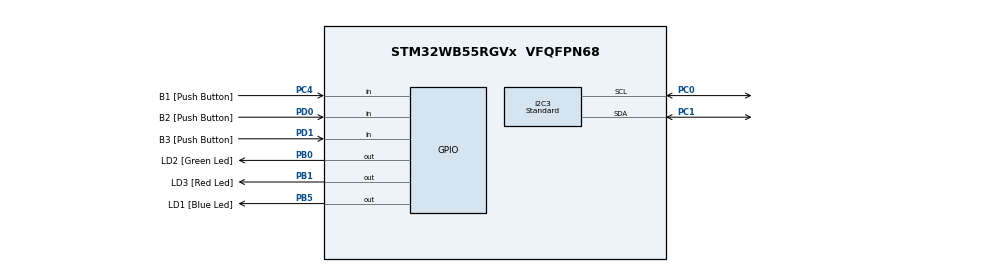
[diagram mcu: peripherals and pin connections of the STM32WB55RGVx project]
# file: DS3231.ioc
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I2C3.I2C_Speed_Mode=I2C_Standard
I2C3.Timing=0x00B07CB4
Mcu.Family=STM32WB
Mcu.Name=STM32WB55RGVx
Mcu.Package=VFQFPN68
NUCLEO-WB55RG.VCP=true
NVIC.PriorityGroup=NVIC_PRIORITYGROUP_4
OSC_IN.GPIO_Label=RCC_OSC_IN
OSC_IN.Signal=RCC_OSC_IN
OSC_OUT.GPIO_Label=RCC_OSC_OUT
OSC_OUT.Signal=RCC_OSC_OUT
PA11.GPIO_Label=USB_DM
PA11.Signal=USB_DM
PA12.GPIO_Label=USB_DP
PA12.Signal=USB_DP
PA13.GPIO_Label=JTMS
PA13.Signal=SYS_JTMS-SWDIO
PA14.GPIO_Label=JTCK
PA14.Signal=SYS_JTCK-SWCLK
PB0.GPIO_Label=LD2 [Green Led]
PB0.Signal=GPIO_Output
PB1.GPIO_Label=LD3 [Red Led]
PB1.Signal=GPIO_Output
PB3.GPIO_Label=JTDO
PB3.Signal=SYS_JTDO-SWO
PB5.GPIO_Label=LD1 [Blue Led]
PB5.Signal=GPIO_Output
PB6.Signal=USART1_TX
PB7.Signal=USART1_RX
PC0.Mode=I2C
PC0.Signal=I2C3_SCL
PC1.Mode=I2C
PC1.Signal=I2C3_SDA
PC13.GPIO_Label=SYS_WKUP2
PC13.Signal=SYS_WKUP2
PC14-OSC32_IN.GPIO_Label=RCC_OSC32_IN
PC14-OSC32_IN.Signal=RCC_OSC32_IN
PC15-OSC32_OUT.GPIO_Label=RCC_OSC32_OUT
PC15-OSC32_OUT.Signal=RCC_OSC32_OUT
PC4.GPIO_Label=B1 [Push Button]
PC4.Signal=GPIO_Input
PD0.GPIO_Label=B2 [Push Button]
PD0.Signal=GPIO_Input
PD1.GPIO_Label=B3 [Push Button]
PD1.Signal=GPIO_Input
ProjectManager.HeapSize=0x200
ProjectManager.StackSize=0x400
ProjectManager.TargetToolchain=CMake
RCC.ADCFreq_Value=128000000
RCC.AHBFreq_Value=32000000
RCC.APB1Freq_Value=32000000
RCC.APB1TimFreq_Value=32000000
RCC.APB2Freq_Value=32000000
RCC.APB2TimFreq_Value=32000000
RCC.APB3Freq_Value=16000000
RCC.CortexFreq_Value=32000000
RCC.HCLKFreq_Value=32000000
RCC.HSE_VALUE=32000000
RCC.HSI48_VALUE=48000000
RCC.HSI_VALUE=16000000
RCC.LSE_VALUE=32768
RCC.MSIClockRange=RCC_MSIRANGE_10
RCC.SMPSCLockSelection=RCC_SMPSCLKSOURCE_HSI
RCC.SMPSCLockSelectionVirtual=RCC_SMPSCLKSOURCE_HSI
RCC.SMPSCLockSelectionVirtualVirtual=RCC_SMPSCLKSOURCE_HSI
RCC.SMPSDivider=1
RCC.SYSCLKFreq_VALUE=32000000
RCC.USBFreq_Value=128000000
RCC.VCOOutputFreq_Value=256000000
VP_MEMORYMAP_VS_MEMORYMAP.Mode=CurAppReg
VP_NUCLEO-WB55RG_VS_BSP_COMMON.Mode=COMMON
board=NUCLEO-WB55RG

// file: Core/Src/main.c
/* USER CODE BEGIN Header */
/**
 ******************************************************************************
 * @file           : main.c
 * @brief          : Main program body
 ******************************************************************************
 * @attention
 *w
 * Copyright (c) 2025 STMicroelectronics.
 * All rights reserved.
 *
 * This software is licensed under terms that can be found in the LICENSE file
 * in the root directory of this software component.
 * If no LICENSE file comes with this software, it is provided AS-IS.
 *
 ******************************************************************************
 */
/* USER CODE END Header */
#include "main.h"
#include "ds3231_lib.h"

time_now_t now;
/* USER CODE BEGIN PTD */
bool status = false;

/* USER CODE END PTD */

// DS3231_Handle_t handle;

COM_InitTypeDef BspCOMInit;
I2C_HandleTypeDef hi2c3;

void SystemClock_Config(void);
void PeriphCommonClock_Config(void);
static void MX_GPIO_Init(void);
static void MX_I2C3_Init(void);
static void MX_BSP(void);
void scan_I2C_bus();

int main(void)
{

  /* MCU Configuration--------------------------------------------------------*/

  /* Reset of all peripherals, Initializes the Flash interface and the Systick. */
  HAL_Init();

  /* Configure the system clock */
  SystemClock_Config();

  /* Configure the peripherals common clocks */
  PeriphCommonClock_Config();

  /* Initialize all configured peripherals */
  MX_GPIO_Init();
  MX_I2C3_Init();
  MX_BSP();

  status = DS3231_Init(&hi2c3);
  if (!status)
  {
    printf("Could not find a valid RTC Module!\r\n");
    while (1)
      ;
  }
  printf("RTC Module Detected!\r\n");

  // setTime(23, 45, 12);

  while (1)
  {
    Date_now = getTime;

    Date_now(&now);

    printf("%02d\r\n", now.getSeconds);

    HAL_Delay(1000);

  }
}

void SystemClock_Config(void)
{
  RCC_OscInitTypeDef RCC_OscInitStruct = {0};
  RCC_ClkInitTypeDef RCC_ClkInitStruct = {0};

  /** Configure the main internal regulator output voltage
   */
  __HAL_PWR_VOLTAGESCALING_CONFIG(PWR_REGULATOR_VOLTAGE_SCALE1);

  /** Initializes the RCC Oscillators according to the specified parameters
   * in the RCC_OscInitTypeDef structure.
   */
  RCC_OscInitStruct.OscillatorType = RCC_OSCILLATORTYPE_HSI | RCC_OSCILLATORTYPE_MSI;
  RCC_OscInitStruct.HSIState = RCC_HSI_ON;
  RCC_OscInitStruct.MSIState = RCC_MSI_ON;
  RCC_OscInitStruct.HSICalibrationValue = RCC_HSICALIBRATION_DEFAULT;
  RCC_OscInitStruct.MSICalibrationValue = RCC_MSICALIBRATION_DEFAULT;
  RCC_OscInitStruct.MSIClockRange = RCC_MSIRANGE_10;
  RCC_OscInitStruct.PLL.PLLState = RCC_PLL_NONE;
  if (HAL_RCC_OscConfig(&RCC_OscInitStruct) != HAL_OK)
  {
    Error_Handler();
  }

  /** Configure the SYSCLKSource, HCLK, PCLK1 and PCLK2 clocks dividers
   */
  RCC_ClkInitStruct.ClockType = RCC_CLOCKTYPE_HCLK4 | RCC_CLOCKTYPE_HCLK2 | RCC_CLOCKTYPE_HCLK | RCC_CLOCKTYPE_SYSCLK | RCC_CLOCKTYPE_PCLK1 | RCC_CLOCKTYPE_PCLK2;
  RCC_ClkInitStruct.SYSCLKSource = RCC_SYSCLKSOURCE_MSI;
  RCC_ClkInitStruct.AHBCLKDivider = RCC_SYSCLK_DIV1;
  RCC_ClkInitStruct.APB1CLKDivider = RCC_HCLK_DIV1;
  RCC_ClkInitStruct.APB2CLKDivider = RCC_HCLK_DIV1;
  RCC_ClkInitStruct.AHBCLK2Divider = RCC_SYSCLK_DIV1;
  RCC_ClkInitStruct.AHBCLK4Divider = RCC_SYSCLK_DIV1;

  if (HAL_RCC_ClockConfig(&RCC_ClkInitStruct, FLASH_LATENCY_1) != HAL_OK)
  {
    Error_Handler();
  }
}

void PeriphCommonClock_Config(void)
{
  RCC_PeriphCLKInitTypeDef PeriphClkInitStruct = {0};

  /** Initializes the peripherals clock
   */
  PeriphClkInitStruct.PeriphClockSelection = RCC_PERIPHCLK_SMPS;
  PeriphClkInitStruct.SmpsClockSelection = RCC_SMPSCLKSOURCE_HSI;
  PeriphClkInitStruct.SmpsDivSelection = RCC_SMPSCLKDIV_RANGE0;

  if (HAL_RCCEx_PeriphCLKConfig(&PeriphClkInitStruct) != HAL_OK)
  {
    Error_Handler();
  }
}

static void MX_I2C3_Init(void)
{

  hi2c3.Instance = I2C3;
  hi2c3.Init.Timing = 0x00B07CB4;
  hi2c3.Init.OwnAddress1 = 0;
  hi2c3.Init.AddressingMode = I2C_ADDRESSINGMODE_7BIT;
  hi2c3.Init.DualAddressMode = I2C_DUALADDRESS_DISABLE;
  hi2c3.Init.OwnAddress2 = 0;
  hi2c3.Init.OwnAddress2Masks = I2C_OA2_NOMASK;
  hi2c3.Init.GeneralCallMode = I2C_GENERALCALL_DISABLE;
  hi2c3.Init.NoStretchMode = I2C_NOSTRETCH_DISABLE;
  if (HAL_I2C_Init(&hi2c3) != HAL_OK)
  {
    Error_Handler();
  }

  /** Configure Analogue filter
   */
  if (HAL_I2CEx_ConfigAnalogFilter(&hi2c3, I2C_ANALOGFILTER_ENABLE) != HAL_OK)
  {
    Error_Handler();
  }

  /** Configure Digital filter
   */
  if (HAL_I2CEx_ConfigDigitalFilter(&hi2c3, 0) != HAL_OK)
  {
    Error_Handler();
  }
}

static void MX_BSP(void)
{
  /* USER CODE BEGIN I2C3_Init 2 */
  /* Initialize COM1 port (115200, 8 bits (7-bit data + 1 stop bit), no parity */
  BspCOMInit.BaudRate = 115200;
  BspCOMInit.WordLength = COM_WORDLENGTH_8B;
  BspCOMInit.StopBits = COM_STOPBITS_1;
  BspCOMInit.Parity = COM_PARITY_NONE;
  BspCOMInit.HwFlowCtl = COM_HWCONTROL_NONE;
  if (BSP_COM_Init(COM1, &BspCOMInit) != BSP_ERROR_NONE)
  {
    Error_Handler();
  }
  /* USER CODE END I2C3_Init 2 */
}

static void MX_GPIO_Init(void)
{
  GPIO_InitTypeDef GPIO_InitStruct = {0};

  /* GPIO Ports Clock Enable */
  __HAL_RCC_GPIOC_CLK_ENABLE();
  __HAL_RCC_GPIOB_CLK_ENABLE();
  __HAL_RCC_GPIOA_CLK_ENABLE();
  __HAL_RCC_GPIOD_CLK_ENABLE();

  /*Configure GPIO pin Output Level */
  HAL_GPIO_WritePin(GPIOB, LD2_Pin | LD3_Pin | LD1_Pin, GPIO_PIN_RESET);

  /*Configure GPIO pin : B1_Pin */
  GPIO_InitStruct.Pin = B1_Pin;
  GPIO_InitStruct.Mode = GPIO_MODE_INPUT;
  GPIO_InitStruct.Pull = GPIO_NOPULL;
  HAL_GPIO_Init(B1_GPIO_Port, &GPIO_InitStruct);

  /*Configure GPIO pins : LD2_Pin LD3_Pin LD1_Pin */
  GPIO_InitStruct.Pin = LD2_Pin | LD3_Pin | LD1_Pin;
  GPIO_InitStruct.Mode = GPIO_MODE_OUTPUT_PP;
  GPIO_InitStruct.Pull = GPIO_NOPULL;
  GPIO_InitStruct.Speed = GPIO_SPEED_FREQ_LOW;
  HAL_GPIO_Init(GPIOB, &GPIO_InitStruct);

  /*Configure GPIO pins : USB_DM_Pin USB_DP_Pin */
  GPIO_InitStruct.Pin = USB_DM_Pin | USB_DP_Pin;
  GPIO_InitStruct.Mode = GPIO_MODE_AF_PP;
  GPIO_InitStruct.Pull = GPIO_NOPULL;
  GPIO_InitStruct.Speed = GPIO_SPEED_FREQ_LOW;
  GPIO_InitStruct.Alternate = GPIO_AF10_USB;
  HAL_GPIO_Init(GPIOA, &GPIO_InitStruct);

  /*Configure GPIO pins : B2_Pin B3_Pin */
  GPIO_InitStruct.Pin = B2_Pin | B3_Pin;
  GPIO_InitStruct.Mode = GPIO_MODE_INPUT;
  GPIO_InitStruct.Pull = GPIO_NOPULL;
  HAL_GPIO_Init(GPIOD, &GPIO_InitStruct);

}

/* USER CODE BEGIN 4 */
void scan_I2C_bus()
{
  printf("Scanning I2C bus...\r\n");

  for (uint8_t addr = 1; addr < 127; addr++)
  {
    if (HAL_I2C_IsDeviceReady(&hi2c3, (addr << 1), 1, HAL_MAX_DELAY) == HAL_OK)
    {
      printf("Device found at 0x%02X\r\n", addr);
    }
  }

  printf("Scan complete.\r\n");
}
/* USER CODE END 4 */

void Error_Handler(void)
{
  __disable_irq();
  while (1)
  {
  }
}
